# CY8C5268LTI_LP030 register map
File version: 0.1
Registers are 8-bit, read-write, no defined reset value unless marked. A register's access mark holds for its fields unless they carry their own. Offsets are from the block's base; [hi:lo] are bit positions.

## UART_TIMER
Base 0x400043A3
0x00 UART_TIMER_GLOBAL_ENABLE — PM.ACT.CFG
  [3:0] en_timer — Enable timer/counters.
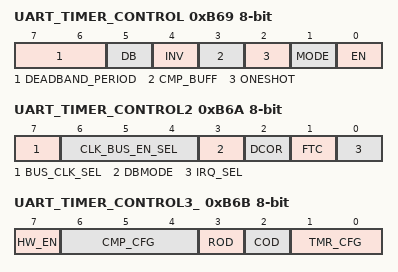
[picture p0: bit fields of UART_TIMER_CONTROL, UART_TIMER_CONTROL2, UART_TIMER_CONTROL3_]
0xB69 UART_TIMER_CONTROL — TMRx.CFG0
  [7:6] DEADBAND_PERIOD
  [5] DB — Deadband mode--Deadband phases phi1 and phi2 are outputted on CMP and TC output pins respectively.
    0=Timer (CMP and TC are output.); 1=Deadband (PHI1 (instead of CMP) and PHI2 (instead of TC) are output.)
  [4] INV — Invert sense of TIMEREN signal
  [3] CMP_BUFF — Buffer compare register. Compare register updates only on timer terminal count.
  [2] ONESHOT — Timer stops upon reaching stop condition defined by TMR_CFG bits. Can be restarted by asserting TIMER RESET or disabling and re-enabling block.
  [1] MODE — Mode. (0 = Timer; 1 = Comparator)
    0=Timer mode. CNT/CMP register holds timer count value.; 1=Comparator mode. CNT/CMP register holds comparator threshold value.
  [0] EN — Enables timer/comparator.
0xB6A UART_TIMER_CONTROL2 — TMRx.CFG1
  [7] BUS_CLK_SEL — Bus Clock selection.
  [6:4] CLK_BUS_EN_SEL — Digital Global Clock selection.
  [3] DBMODE — Deadband mode (asynchronous/synchronous). CMP output pin is also affected when not in deadband mode (CFG0.DEADBAND).
  [2] DCOR — Disable Clear on Read (DCOR) of Status Register SR0.
  [1] FTC — First Terminal Count (FTC). Setting this bit forces a single pulse on the TC pin when first enabled.
    0=Disable_FTC (Disable the single cycle pulse, which signifies the timer is starting.); 1=Enable_FTC (Enable the single cycle pulse, which signifies the timer is starting.)
  [0] IRQ_SEL — Irq selection. (0 = raw interrupts; 1 = status register interrupts)
0xB6B UART_TIMER_CONTROL3_ — TMRx.CFG2
  [7] HW_EN — When set Timer Enable controls counting.
  [6:4] CMP_CFG — Comparator configurations
    0=Equal (Compare Equal); 1=Less_than (Compare Less Than); 2=Less_than_or_equal (Compare Less Than or Equal .); 3=Greater (Compare Greater Than .); 4=Greater_than_or_equal (Compare Greater Than or Equal)
  [3] ROD — Reset On Disable (ROD). Resets internal state of output logic
  [2] COD — Clear On Disable (COD). Clears or gates outputs to zero.
  [1:0] TMR_CFG — Timer configuration (MODE = 0): 000 = Continuous; 001 = Pulsewidth; 010 = Period; 011 = Stop on IRQ
    0=Continuous (Timer runs while EN bit of CFG0 register is set to '1'.); 1=Pulsewidth (Timer runs from positive to negative edge of TIMEREN.); 2=Period (Timer runs from positive to positive edge of TIMEREN.); 3=Irq (Timer runs until IRQ.)
0xB6D UART_TIMER_PERIOD — TMRx.PER0 - Assigned Period
0xB6F UART_TIMER_COUNTER — TMRx.CNT_CMP0 - Current Down Counter Value

## EZI2Cs
Base 0x400049C8
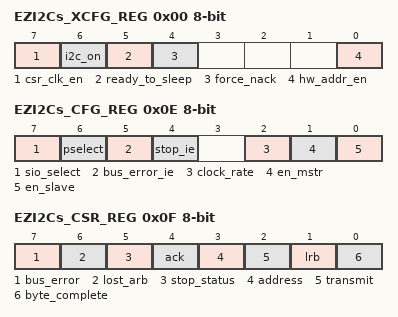
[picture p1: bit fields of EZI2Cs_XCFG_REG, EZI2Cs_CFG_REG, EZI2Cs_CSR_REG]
0x00 EZI2Cs_XCFG_REG — Extended Configuration Register: I2C_XCFG
  [7] csr_clk_en, [6] i2c_on, [5] ready_to_sleep ro, [4] force_nack, [0] hw_addr_en
0x02 EZI2Cs_ADDR_REG — Slave Adddress Register: I2C_ADR
  [6:0] slave_address — This register holds the slave's 7-bit address.
0x0E EZI2Cs_CFG_REG — Configuration Register: I2C_CFG
  [7] sio_select, [6] pselect, [5] bus_error_ie, [4] stop_ie, [2] clock_rate, [1] en_mstr, [0] en_slave
0x0F EZI2Cs_CSR_REG — Control and Status Register: I2C_CSR
  [7] bus_error, [6] lost_arb, [5] stop_status, [4] ack, [3] address, [2] transmit, [1] lrb, [0] byte_complete
0x10 EZI2Cs_DATA_REG — Data Register: I2C_D
  [7:0] data — This register provides read/write access to the Shift register.

## UART_1 — UART
Base 0x40006423
0x00 RX_UART_1_RX_ADDRESS1 — RX Address1 Register
0x10 RX_UART_1_RX_ADDRESS2 — RX Address2 Register
0x20 RX_UART_1_RX_DATA — RX Data Register
0x22 TX_UART_1_TX_DATA — TX Data Register
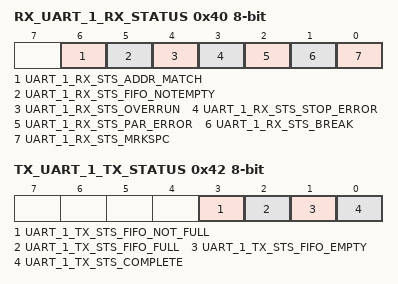
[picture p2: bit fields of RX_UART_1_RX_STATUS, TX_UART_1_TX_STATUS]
0x40 RX_UART_1_RX_STATUS — RX status register
  [6] UART_1_RX_STS_ADDR_MATCH ro, [5] UART_1_RX_STS_FIFO_NOTEMPTY ro, [4] UART_1_RX_STS_OVERRUN ro, [3] UART_1_RX_STS_STOP_ERROR ro, [2] UART_1_RX_STS_PAR_ERROR ro, [1] UART_1_RX_STS_BREAK ro, [0] UART_1_RX_STS_MRKSPC ro
0x42 TX_UART_1_TX_STATUS — TX status register
  [3] UART_1_TX_STS_FIFO_NOT_FULL ro, [2] UART_1_TX_STS_FIFO_FULL ro, [1] UART_1_TX_STS_FIFO_EMPTY ro, [0] UART_1_TX_STS_COMPLETE ro
